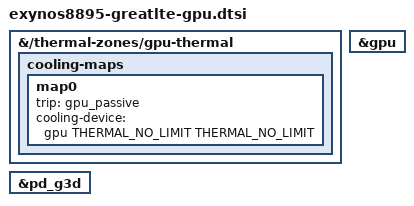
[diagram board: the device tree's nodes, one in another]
// SPDX-License-Identifier: GPL-2.0 OR BSD-3-Clause
/*
 * Samsung Galaxy Note 8 (SM-N950N) GPU
 */

&{/thermal-zones/gpu-thermal} {
	cooling-maps {
		map0 {
			trip = <&gpu_passive>;
			cooling-device = <&gpu THERMAL_NO_LIMIT THERMAL_NO_LIMIT>;
		};
	};
};

&gpu {
	status = "okay";
};

&pd_g3d {
	status = "okay";
};
